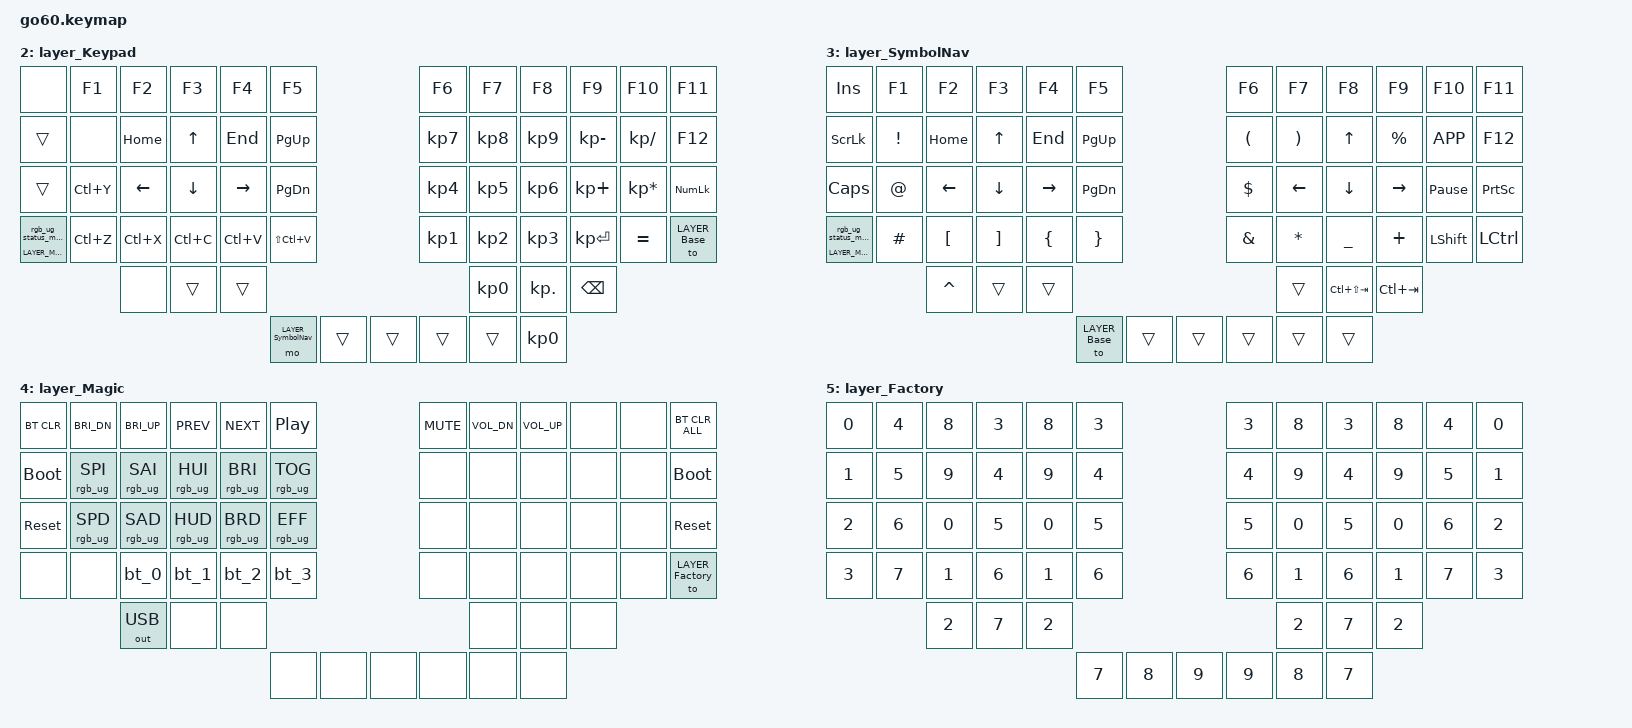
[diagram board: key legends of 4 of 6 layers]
/*
 * Copyright (c) 2020 The ZMK Contributors
 *
 * SPDX-License-Identifier: MIT
 */

#include <behaviors.dtsi>

#include <dt-bindings/zmk/bt.h>
#include <dt-bindings/zmk/ext_power.h>
#include <dt-bindings/zmk/keys.h>
#include <dt-bindings/zmk/outputs.h>
#include <dt-bindings/zmk/rgb.h>
#include <dt-bindings/zmk/input_transform.h>
#include <dt-bindings/zmk/pointing.h>

#include <input/processors.dtsi>
#include <zephyr/dt-bindings/input/input-event-codes.h>

// layers
#define LAYER_Base 0
#define LAYER_Enthium 2
#define LAYER_Keypad 3
#define LAYER_SymbolNav 4
#define LAYER_Magic 5
#define LAYER_Factory 6


#define POS_LH_C6R1 0
#define POS_LH_C5R1 1
#define POS_LH_C4R1 2
#define POS_LH_C3R1 3
#define POS_LH_C2R1 4
#define POS_LH_C1R1 5
#define POS_RH_C1R1 6
#define POS_RH_C2R1 7
#define POS_RH_C3R1 8
#define POS_RH_C4R1 9
#define POS_RH_C5R1 10
#define POS_RH_C6R1 11
#define POS_LH_C6R2 12
#define POS_LH_C5R2 13
#define POS_LH_C4R2 14
#define POS_LH_C3R2 15
#define POS_LH_C2R2 16
#define POS_LH_C1R2 17
#define POS_RH_C1R2 18
#define POS_RH_C2R2 19
#define POS_RH_C3R2 20
#define POS_RH_C4R2 21
#define POS_RH_C5R2 22
#define POS_RH_C6R2 23
#define POS_LH_C6R3 24
#define POS_LH_C5R3 25
#define POS_LH_C4R3 26
#define POS_LH_C3R3 27
#define POS_LH_C2R3 28
#define POS_LH_C1R3 29
#define POS_RH_C1R3 30
#define POS_RH_C2R3 31
#define POS_RH_C3R3 32
#define POS_RH_C4R3 33
#define POS_RH_C5R3 34
#define POS_RH_C6R3 35
#define POS_LH_C6R4 36
#define POS_LH_C5R4 37
#define POS_LH_C4R4 38
#define POS_LH_C3R4 39
#define POS_LH_C2R4 40
#define POS_LH_C1R4 41
#define POS_RH_C1R4 42
#define POS_RH_C2R4 43
#define POS_RH_C3R4 44
#define POS_RH_C4R4 45
#define POS_RH_C5R4 46
#define POS_RH_C6R4 47
#define POS_LH_C4R5 48
#define POS_LH_C3R5 49
#define POS_LH_C2R5 50
#define POS_RH_C2R5 51
#define POS_RH_C3R5 52
#define POS_RH_C4R5 53
#define POS_LH_T1 54
#define POS_LH_T2 55
#define POS_LH_T3 56
#define POS_RH_T3 57
#define POS_RH_T2 58
#define POS_RH_T1 59

/ {
    combos {
        compatible = "zmk,combos";

        // cmb_enter
        combo_cmb_enter {
            key-positions = <POS_RH_C2R3 POS_RH_C3R3 POS_RH_C4R3>;
            bindings = <&kp RET>;
        };



        // cmb_oe
        combo_cmb_oe {
            key-positions = <POS_RH_C2R2 POS_RH_C3R2>;
            bindings = <&oe>;
        };

        // cmb_ae
        combo_cmb_ae {
            key-positions = <POS_RH_C2R4 POS_RH_C4R4>;
            bindings = <&ae>;
        };
    };
};

/ {
    input_processors {
        zip_click_to_right_click_mapper: zip_click_to_right_click_mapper {
            compatible = "zmk,input-processor-code-mapper";
            #input-processor-cells = <0>;
            type = <INPUT_EV_KEY>;
            map = <INPUT_BTN_0 INPUT_BTN_1>;
        };
    };

    behaviors {
        arcane: arcane {
             compatible = "zmk,behavior-adaptive-key";
             #binding-cells = <0>;
             bindings = <&kp N>;
             arc_eu { trigger-keys = <E>; max-prior-idle-ms = <500>; bindings = <&kp U>; };
             arc_ue { trigger-keys = <U>; max-prior-idle-ms = <500>; bindings = <&kp E>; };
             arc_rl { trigger-keys = <R>; max-prior-idle-ms = <500>; bindings = <&kp L>; };
             arc_kt { trigger-keys = <K>; max-prior-idle-ms = <500>; bindings = <&kp T>; };
        };

        magic: magic {
            compatible = "zmk,behavior-hold-tap";
            #binding-cells = <2>;
            flavor = "tap-preferred";
            tapping-term-ms = <200>;
            bindings = <&mo>, <&rgb_ug_status_macro>;
        };

        keypad_td: keypad_td {
            compatible = "zmk,behavior-tap-dance";
            #binding-cells = <0>;
            tapping-term-ms = <200>;
            bindings = <&mo LAYER_Keypad>, <&to LAYER_Keypad>;
        };

        symbol_nav_td: symbol_nav_td {
            compatible = "zmk,behavior-tap-dance";
            #binding-cells = <0>;
            tapping-term-ms = <200>;
            bindings = <&mo LAYER_SymbolNav>, <&to LAYER_SymbolNav>;
        };

        bt_0: bt_0 {
            compatible = "zmk,behavior-tap-dance";
            #binding-cells = <0>;
            tapping-term-ms = <200>;
            bindings = <&bt_select_0>, <&bt BT_DISC 0>;
        };
        bt_1: bt_1 {
            compatible = "zmk,behavior-tap-dance";
            #binding-cells = <0>;
            tapping-term-ms = <200>;
            bindings = <&bt_select_1>, <&bt BT_DISC 1>;
        };
        bt_2: bt_2 {
            compatible = "zmk,behavior-tap-dance";
            #binding-cells = <0>;
            tapping-term-ms = <200>;
            bindings = <&bt_select_2>, <&bt BT_DISC 2>;
        };
        bt_3: bt_3 {
            compatible = "zmk,behavior-tap-dance";
            #binding-cells = <0>;
            tapping-term-ms = <200>;
            bindings = <&bt_select_3>, <&bt BT_DISC 3>;
        };
    };

    macros {
        rgb_ug_status_macro: rgb_ug_status_macro {
            compatible = "zmk,behavior-macro";
            #binding-cells = <0>;
            bindings = <&rgb_ug RGB_STATUS>;
        };

        bt_select_0: bt_select_0 {
            compatible = "zmk,behavior-macro";
            #binding-cells = <0>;
            bindings
                = <&out OUT_BLE>,
                  <&bt BT_SEL 0>;
        };
        bt_select_1: bt_select_1 {
            compatible = "zmk,behavior-macro";
            #binding-cells = <0>;
            bindings
                = <&out OUT_BLE>,
                  <&bt BT_SEL 1>;
        };
        bt_select_2: bt_select_2 {
            compatible = "zmk,behavior-macro";
            #binding-cells = <0>;
            bindings
                = <&out OUT_BLE>,
                  <&bt BT_SEL 2>;
        };
        bt_select_3: bt_select_3 {
            compatible = "zmk,behavior-macro";
            #binding-cells = <0>;
            bindings
                = <&out OUT_BLE>,
                  <&bt BT_SEL 3>;
        };
                // oe
        oe: oe {
            label = "&OE";
            compatible = "zmk,behavior-macro";
            #binding-cells = <0>;
            bindings = <&kt RALT>
                , <&kp O>
                , <&kt RALT>;
        };

        // ae
        ae: ae {
            label = "&AE";
            compatible = "zmk,behavior-macro";
            #binding-cells = <0>;
            bindings = <&sk RALT>
                , <&kp A>;
        };

        // ue
        ue: ue {
            label = "&UE";
            compatible = "zmk,behavior-macro";
            #binding-cells = <0>;
            bindings = <&sk RALT>
                , <&kp U>;
        };

        // sz
        sz: sz {
            label = "&SZ";
            compatible = "zmk,behavior-macro";
            #binding-cells = <0>;
            bindings = <&sk RALT>
                , <&kp S>;
        };

    };

    keymap {
        compatible = "zmk,keymap";
        layer_Base {
            bindings = <
            &kp EQUAL  &kp N1     &kp N2   &kp N3    &kp N4  &kp N5                                                       &kp N6     &kp N7     &kp N8    &kp N9    &kp N0    &to 1
              &kp TAB   &kp V      &kp M    &kp L     &kp C   &kp P                                                       &kp B     &arcane      &kp U     &kp O     &kp Q     &kp BSLH
              &kp ESC   &kp S      &kp T    &kp N     &kp D   &kp Y                                                       &kp F       &kp N      &kp E     &kp A     &kp I      &kp SQT
 &magic LAYER_Magic 0   &kp X      &kp K    &kp J     &kp G   &kp W                                                       &kp X       &kp H  &kp COMMA   &kp DOT   &kp SQT   &keypad_td
                               &kp GRAVE  &kp DEL  &kp BSPC                                                                        &kp LGUI   &kp LBKT  &kp RBKT
                                                   &kp R &symbol_nav_td &kp LCTRL              &kp LALT  &kp SPACE  &sk LSFT  &lt LAYER_Keypad SPACE
            >;
        };
        
        layer_Enthium{
            bindings = <
            &kp EQUAL  &kp N1     &kp N2   &kp N3    &kp N4  &kp N5                                                       &kp N6     &kp N7     &kp N8    &kp N9    &kp N0    &to 0
              &kp TAB   &kp Z      &kp P    &kp D     &kp L   &kp X                                                       &kp EQUAL   &kp U      &kp O     &kp Y     &kp Q     &kp BSLH
                &kp W   &kp S      &kp N    &kp T     &kp H   &kp K                                                       &kp MINUS   &kp I      &kp E     &kp A     &kp C      &kp B
 &magic LAYER_Magic 0   &kp V      &kp F    &kp G     &kp M   &kp J                                                       &kp SCLN    &kp SLASH  &kp DOT   &kp COMMA   &kp SQT   &keypad_td
                               &kp GRAVE  &kp DEL  &kp BSPC                                                                        &kp LGUI   &kp LBKT  &kp RBKT
                                                   &kp R &symbol_nav_td &kp LCTRL              &kp LALT  &kp SPACE  &sk LSFT  &lt LAYER_Keypad SPACE
            >;
        };

        layer_Keypad {
            bindings = <
                &none     &kp F1     &kp F2     &kp F3     &kp F4         &kp F5                                                 &kp F6     &kp F7      &kp F8        &kp F9          &kp F10        &kp F11
               &trans      &none   &kp HOME     &kp UP    &kp END      &kp PG_UP                                              &kp KP_N7  &kp KP_N8   &kp KP_N9  &kp KP_MINUS     &kp KP_SLASH        &kp F12
               &trans  &kp LC(Y)   &kp LEFT   &kp DOWN  &kp RIGHT      &kp PG_DN                                              &kp KP_N4  &kp KP_N5   &kp KP_N6   &kp KP_PLUS  &kp KP_MULTIPLY     &kp KP_NUM
 &magic LAYER_Magic 0  &kp LC(Z)  &kp LC(X)  &kp LC(C)  &kp LC(V)  &kp LS(LC(V))                                              &kp KP_N1  &kp KP_N2   &kp KP_N3  &kp KP_ENTER        &kp EQUAL &to LAYER_Base
                                      &none     &trans     &trans                                                                        &kp KP_N0  &kp KP_DOT      &kp BSPC
                                                             &mo LAYER_SymbolNav  &trans  &trans              &trans  &trans  &kp KP_N0
            >;
        };

        layer_SymbolNav {
            bindings = <
              &kp INS    &kp F1     &kp F2    &kp F3     &kp F4     &kp F5                                       &kp F6    &kp F7           &kp F8       &kp F9          &kp F10    &kp F11
             &kp SLCK  &kp EXCL   &kp HOME    &kp UP    &kp END  &kp PG_UP                                     &kp LPAR  &kp RPAR           &kp UP    &kp PRCNT        &kp K_APP    &kp F12
             &kp CAPS    &kp AT   &kp LEFT  &kp DOWN  &kp RIGHT  &kp PG_DN                                     &kp DLLR  &kp LEFT         &kp DOWN    &kp RIGHT  &kp PAUSE_BREAK  &kp PSCRN
 &magic LAYER_Magic 0  &kp HASH   &kp LBKT  &kp RBKT   &kp LBRC   &kp RBRC                                     &kp AMPS  &kp STAR        &kp UNDER     &kp PLUS        &kp LSHFT  &kp LCTRL
                                 &kp CARET    &trans     &trans                                                            &trans  &kp LC(LS(TAB))  &kp LC(TAB)
                                                            &to LAYER_Base  &trans  &trans       &trans  &trans  &trans
            >;
        };

        layer_Magic {
            bindings = <
  &bt BT_CLR     &kp C_BRI_DN     &kp C_BRI_UP       &kp C_PREV       &kp C_NEXT         &kp C_PP                                &kp C_MUTE  &kp C_VOL_DN  &kp C_VOL_UP   &none   &none    &bt BT_CLR_ALL
 &bootloader  &rgb_ug RGB_SPI  &rgb_ug RGB_SAI  &rgb_ug RGB_HUI  &rgb_ug RGB_BRI  &rgb_ug RGB_TOG                                     &none         &none         &none   &none   &none       &bootloader
  &sys_reset  &rgb_ug RGB_SPD  &rgb_ug RGB_SAD  &rgb_ug RGB_HUD  &rgb_ug RGB_BRD  &rgb_ug RGB_EFF                                     &none         &none         &none   &none   &none        &sys_reset
       &none            &none            &bt_0            &bt_1            &bt_2            &bt_3                                     &none         &none         &none   &none   &none &to LAYER_Factory
                                  &out OUT_USB            &none            &none                                                                    &none         &none   &none
                                                                                            &none   &none   &none     &none   &none   &none
            >;
        };

        layer_Factory {
            bindings = <
 &kp N0  &kp N4  &kp N8  &kp N3  &kp N8  &kp N3                                       &kp N3  &kp N8  &kp N3  &kp N8  &kp N4  &kp N0
 &kp N1  &kp N5  &kp N9  &kp N4  &kp N9  &kp N4                                       &kp N4  &kp N9  &kp N4  &kp N9  &kp N5  &kp N1
 &kp N2  &kp N6  &kp N0  &kp N5  &kp N0  &kp N5                                       &kp N5  &kp N0  &kp N5  &kp N0  &kp N6  &kp N2
 &kp N3  &kp N7  &kp N1  &kp N6  &kp N1  &kp N6                                       &kp N6  &kp N1  &kp N6  &kp N1  &kp N7  &kp N3
                 &kp N2  &kp N7  &kp N2                                                       &kp N2  &kp N7  &kp N2
                                          &kp N7  &kp N8  &kp N9      &kp N9  &kp N8  &kp N7
            >;
        };
    };
};

&cirque_rh_listener {
    input-processors = <&zip_xy_scaler 3 1>;
    layer_2 {
        layers = <2>;
        input-processors = <&zip_xy_scaler 9 1>;
    };
};

&cirque_lh_listener {
    input-processors = <&zip_xy_to_scroll_mapper>, <&zip_xy_scaler 1 8>, <&zip_click_to_right_click_mapper>;
    layer_4 {
        layers = <4>;
        input-processors = <&zip_xy_scaler 3 1>;
    };
};
